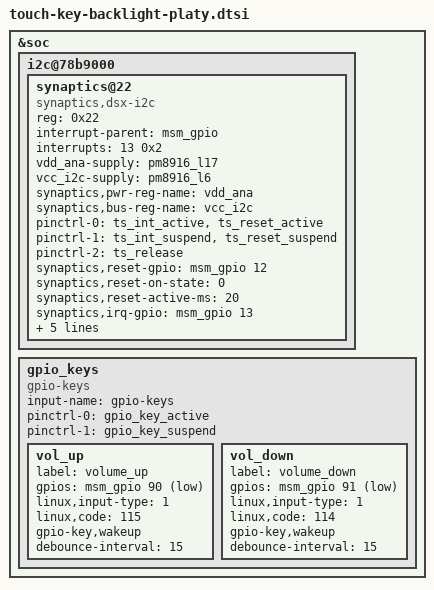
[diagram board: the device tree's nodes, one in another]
&soc {
	i2c@78b9000 { /* BLSP1 QUP5 */
		synaptics@22 {
			compatible = "synaptics,dsx-i2c";
			reg = <0x22>;
			interrupt-parent = <&msm_gpio>;
			interrupts = <13 0x2>;
			vdd_ana-supply = <&pm8916_l17>;
			vcc_i2c-supply = <&pm8916_l6>;
			synaptics,pwr-reg-name = "vdd_ana";
			synaptics,bus-reg-name = "vcc_i2c";
			pinctrl-names = "pmx_ts_active","pmx_ts_suspend","pmx_ts_release";
			pinctrl-0 = <&ts_int_active &ts_reset_active>;
			pinctrl-1 = <&ts_int_suspend &ts_reset_suspend>;
			pinctrl-2 = <&ts_release>;
			synaptics,reset-gpio = <&msm_gpio 12 0x0>;
			synaptics,reset-on-state = <0>;
			synaptics,reset-active-ms = <20>;
			synaptics,irq-gpio = <&msm_gpio 13 0x2008>;
			synaptics,irq-on-state = <0>;
			synaptics,irq-flags = <0x2008>; /* IRQF_ONESHOT | IRQF_TRIGGER_LOW */
			synaptics,power-delay-ms = <200>;
			synaptics,reset-delay-ms = <200>;
			synaptics,cap-button-codes = <158 102 187>;
		};
	};

	gpio_keys {
		compatible = "gpio-keys";
		input-name = "gpio-keys";
		pinctrl-names = "tlmm_gpio_key_active","tlmm_gpio_key_suspend";
		pinctrl-0 = <&gpio_key_active>;
		pinctrl-1 = <&gpio_key_suspend>;

		vol_up {
			label = "volume_up";
			gpios = <&msm_gpio 90 0x1>;
			linux,input-type = <1>;
			linux,code = <115>;
			gpio-key,wakeup;
			debounce-interval = <15>;
		};
		vol_down {
			label = "volume_down";
			gpios = <&msm_gpio 91 0x1>;
			linux,input-type = <1>;
			linux,code = <114>;
			gpio-key,wakeup;
			debounce-interval = <15>;
		};
	};
};



